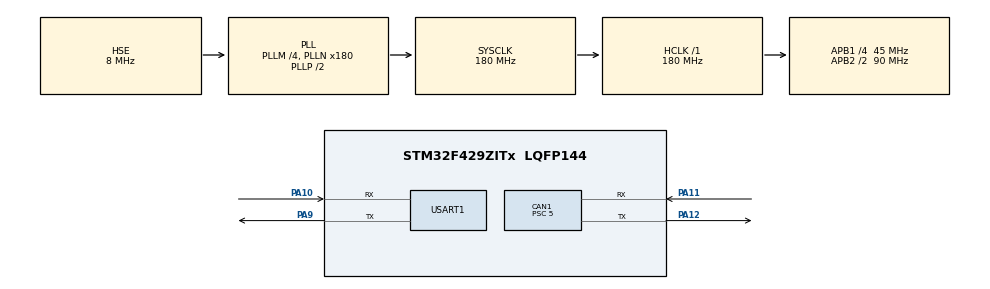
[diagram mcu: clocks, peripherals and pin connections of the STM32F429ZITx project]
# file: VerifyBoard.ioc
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CAN1.BS1=CAN_BS1_13TQ
CAN1.BS2=CAN_BS2_4TQ
CAN1.CalculateBaudRate=500000
CAN1.CalculateTimeBit=2000
CAN1.CalculateTimeQuantum=111.11111111111111
CAN1.Prescaler=5
CAN1.SJW=CAN_SJW_2TQ
FREERTOS.Tasks01=CANRcvTask,24,512,CANRcv,Default,NULL,Dynamic,NULL,NULL
FREERTOS.Timers01=CANTransmit_Timer,CANTransmit_Timer_cb,osTimerPeriodic,Default,NULL,Dynamic,NULL
FREERTOS.configTIMER_TASK_PRIORITY=40
FREERTOS.configUSE_NEWLIB_REENTRANT=1
Mcu.Family=STM32F4
Mcu.Name=STM32F429ZITx
Mcu.Package=LQFP144
NVIC.PriorityGroup=NVIC_PRIORITYGROUP_4
NVIC.TIM6_DAC_IRQn=true\:15\:0\:false\:false\:true\:false\:false\:true\:true
NVIC.TimeBase=TIM6_DAC_IRQn
NVIC.TimeBaseIP=TIM6
PA10.Mode=Asynchronous
PA10.Signal=USART1_RX
PA11.Mode=CAN_Activate
PA11.Signal=CAN1_RX
PA12.Mode=CAN_Activate
PA12.Signal=CAN1_TX
PA13.Mode=Serial_Wire
PA13.Signal=SYS_JTMS-SWDIO
PA14.Mode=Serial_Wire
PA14.Signal=SYS_JTCK-SWCLK
PA9.Mode=Asynchronous
PA9.Signal=USART1_TX
PH0/OSC_IN.Mode=HSE-External-Oscillator
PH0/OSC_IN.Signal=RCC_OSC_IN
PH1/OSC_OUT.Mode=HSE-External-Oscillator
PH1/OSC_OUT.Signal=RCC_OSC_OUT
ProjectManager.HeapSize=0x200
ProjectManager.StackSize=0x400
ProjectManager.TargetToolchain=STM32CubeIDE
RCC.48MHZClocksFreq_Value=90000000
RCC.AHBFreq_Value=180000000
RCC.APB1CLKDivider=RCC_HCLK_DIV4
RCC.APB1Freq_Value=45000000
RCC.APB1TimFreq_Value=90000000
RCC.APB2CLKDivider=RCC_HCLK_DIV2
RCC.APB2Freq_Value=90000000
RCC.APB2TimFreq_Value=180000000
RCC.CortexFreq_Value=180000000
RCC.HCLKFreq_Value=180000000
RCC.HSE_VALUE=8000000
RCC.HSI_VALUE=16000000
RCC.LSE_VALUE=32768
RCC.PLLM=4
RCC.PLLN=180
RCC.PLLSourceVirtual=RCC_PLLSOURCE_HSE
RCC.SYSCLKFreq_VALUE=180000000
RCC.SYSCLKSource=RCC_SYSCLKSOURCE_PLLCLK
RCC.VCOOutputFreq_Value=360000000
USART1.VirtualMode=VM_ASYNC
VP_FREERTOS_VS_CMSIS_V2.Mode=CMSIS_V2
VP_SYS_VS_tim6.Mode=TIM6
board=custom

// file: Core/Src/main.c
/* USER CODE BEGIN Header */
/**
  ******************************************************************************
  * @file           : main.c
  * @brief          : Main program body
  ******************************************************************************
  * @attention
  *
  * Copyright (c) 2022 STMicroelectronics.
  * All rights reserved.
  *
  * This software is licensed under terms that can be found in the LICENSE file
  * in the root directory of this software component.
  * If no LICENSE file comes with this software, it is provided AS-IS.
  *
  ******************************************************************************
  */
/* USER CODE END Header */
#include "main.h"
#include "cmsis_os.h"

/* USER CODE BEGIN Includes */
#include "MyPrintf.h"
#include "CANCom.h"
#include <stdlib.h>
/* USER CODE END Includes */

CAN_HandleTypeDef hcan1;

UART_HandleTypeDef huart1;

/* Definitions for CANRcvTask */
osThreadId_t CANRcvTaskHandle;
const osThreadAttr_t CANRcvTask_attributes = {
  .name = "CANRcvTask",
  .stack_size = 512 * 4,
  .priority = (osPriority_t) osPriorityNormal,
};
/* Definitions for CANTransmit_Timer */
osTimerId_t CANTransmit_TimerHandle;
const osTimerAttr_t CANTransmit_Timer_attributes = {
  .name = "CANTransmit_Timer"
};

void SystemClock_Config(void);
static void MX_GPIO_Init(void);
static void MX_CAN1_Init(void);
static void MX_USART1_UART_Init(void);
void CANRcv(void *argument);
void CANTransmit_Timer_cb(void *argument);

int main(void)
{

  /* MCU Configuration--------------------------------------------------------*/

  /* Reset of all peripherals, Initializes the Flash interface and the Systick. */
  HAL_Init();

  /* Configure the system clock */
  SystemClock_Config();

  /* Initialize all configured peripherals */
  MX_GPIO_Init();
  MX_CAN1_Init();
  MX_USART1_UART_Init();

  /* Init scheduler */
  osKernelInitialize();

  /* Create the timer(s) */
  /* creation of CANTransmit_Timer */
  CANTransmit_TimerHandle = osTimerNew(CANTransmit_Timer_cb, osTimerPeriodic, NULL, &CANTransmit_Timer_attributes);

  /* USER CODE BEGIN RTOS_TIMERS */
  /* start timers, add new ones, ... */
  MyPrintf_Init();
  CAN_Config(&hcan1);
  osTimerStart(CANTransmit_TimerHandle, 20);

  /* USER CODE END RTOS_TIMERS */

  /* Create the thread(s) */
  /* creation of CANRcvTask */
  CANRcvTaskHandle = osThreadNew(CANRcv, NULL, &CANRcvTask_attributes);

  /* Start scheduler */
  osKernelStart();

  /* We should never get here as control is now taken by the scheduler */
  /* Infinite loop */
  while (1)
  {

  }
}

void SystemClock_Config(void)
{
  RCC_OscInitTypeDef RCC_OscInitStruct = {0};
  RCC_ClkInitTypeDef RCC_ClkInitStruct = {0};

  /** Configure the main internal regulator output voltage
  */
  __HAL_RCC_PWR_CLK_ENABLE();
  __HAL_PWR_VOLTAGESCALING_CONFIG(PWR_REGULATOR_VOLTAGE_SCALE1);

  /** Initializes the RCC Oscillators according to the specified parameters
  * in the RCC_OscInitTypeDef structure.
  */
  RCC_OscInitStruct.OscillatorType = RCC_OSCILLATORTYPE_HSE;
  RCC_OscInitStruct.HSEState = RCC_HSE_ON;
  RCC_OscInitStruct.PLL.PLLState = RCC_PLL_ON;
  RCC_OscInitStruct.PLL.PLLSource = RCC_PLLSOURCE_HSE;
  RCC_OscInitStruct.PLL.PLLM = 4;
  RCC_OscInitStruct.PLL.PLLN = 180;
  RCC_OscInitStruct.PLL.PLLP = RCC_PLLP_DIV2;
  RCC_OscInitStruct.PLL.PLLQ = 4;
  if (HAL_RCC_OscConfig(&RCC_OscInitStruct) != HAL_OK)
  {
    Error_Handler();
  }

  /** Activate the Over-Drive mode
  */
  if (HAL_PWREx_EnableOverDrive() != HAL_OK)
  {
    Error_Handler();
  }

  /** Initializes the CPU, AHB and APB buses clocks
  */
  RCC_ClkInitStruct.ClockType = RCC_CLOCKTYPE_HCLK|RCC_CLOCKTYPE_SYSCLK
                              |RCC_CLOCKTYPE_PCLK1|RCC_CLOCKTYPE_PCLK2;
  RCC_ClkInitStruct.SYSCLKSource = RCC_SYSCLKSOURCE_PLLCLK;
  RCC_ClkInitStruct.AHBCLKDivider = RCC_SYSCLK_DIV1;
  RCC_ClkInitStruct.APB1CLKDivider = RCC_HCLK_DIV4;
  RCC_ClkInitStruct.APB2CLKDivider = RCC_HCLK_DIV2;

  if (HAL_RCC_ClockConfig(&RCC_ClkInitStruct, FLASH_LATENCY_5) != HAL_OK)
  {
    Error_Handler();
  }
}

static void MX_CAN1_Init(void)
{

  hcan1.Instance = CAN1;
  hcan1.Init.Prescaler = 5;
  hcan1.Init.Mode = CAN_MODE_NORMAL;
  hcan1.Init.SyncJumpWidth = CAN_SJW_2TQ;
  hcan1.Init.TimeSeg1 = CAN_BS1_13TQ;
  hcan1.Init.TimeSeg2 = CAN_BS2_4TQ;
  hcan1.Init.TimeTriggeredMode = DISABLE;
  hcan1.Init.AutoBusOff = DISABLE;
  hcan1.Init.AutoWakeUp = DISABLE;
  hcan1.Init.AutoRetransmission = DISABLE;
  hcan1.Init.ReceiveFifoLocked = DISABLE;
  hcan1.Init.TransmitFifoPriority = DISABLE;
  if (HAL_CAN_Init(&hcan1) != HAL_OK)
  {
    Error_Handler();
  }

}

static void MX_USART1_UART_Init(void)
{

  huart1.Instance = USART1;
  huart1.Init.BaudRate = 115200;
  huart1.Init.WordLength = UART_WORDLENGTH_8B;
  huart1.Init.StopBits = UART_STOPBITS_1;
  huart1.Init.Parity = UART_PARITY_NONE;
  huart1.Init.Mode = UART_MODE_TX_RX;
  huart1.Init.HwFlowCtl = UART_HWCONTROL_NONE;
  huart1.Init.OverSampling = UART_OVERSAMPLING_16;
  if (HAL_UART_Init(&huart1) != HAL_OK)
  {
    Error_Handler();
  }

}

static void MX_GPIO_Init(void)
{

  /* GPIO Ports Clock Enable */
  __HAL_RCC_GPIOH_CLK_ENABLE();
  __HAL_RCC_GPIOA_CLK_ENABLE();

}

void CANRcv(void *argument)
{
  /* USER CODE BEGIN 5 */
  /* Infinite loop */
	MyPrintf("Verify Start Rcv \r\n");
  for(;;)
  {
//	  osDelay(1);
	  CAN_Receive(&hcan1);
  }
  /* USER CODE END 5 */
}

/* CANTransmit_Timer_cb function */
void CANTransmit_Timer_cb(void *argument)
{
  /* USER CODE BEGIN CANTransmit_Timer_cb */
//	MyPrintf("Verify Transmit \r\n");
	CAN_Transmit(&hcan1);
  /* USER CODE END CANTransmit_Timer_cb */
}

void HAL_TIM_PeriodElapsedCallback(TIM_HandleTypeDef *htim)
{
  if (htim->Instance == TIM6) {
    HAL_IncTick();
  }
}

void Error_Handler(void)
{
  __disable_irq();
  while (1)
  {
  }
}
